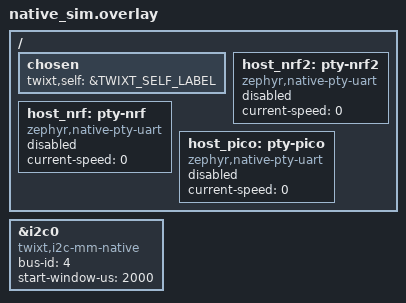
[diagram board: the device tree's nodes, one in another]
/*
 * Copyright (c) 2026 Christoph Jans <jans.christoph@gmail.com>
 *
 * SPDX-License-Identifier: Apache-2.0
 */

/* The bus on native_sim (twixt,i2c-mm-native); TWIXT_SELF_LABEL is mcu_<MCU>. The bridge's
 * ports to the host are PTYs (bridge.overlay enables them):
 * "pty-nrf2 connected to pseudotty: /dev/pts/N"
 */

/ {
	chosen {
		twixt,self = &TWIXT_SELF_LABEL;
	};

	host_nrf2: pty-nrf2 {
		compatible = "zephyr,native-pty-uart";
		current-speed = <0>;
		status = "disabled";
	};

	host_nrf: pty-nrf {
		compatible = "zephyr,native-pty-uart";
		current-speed = <0>;
		status = "disabled";
	};

	host_pico: pty-pico {
		compatible = "zephyr,native-pty-uart";
		current-speed = <0>;
		status = "disabled";
	};
};

&i2c0 {
	compatible = "twixt,i2c-mm-native";
	bus-id = <4>;

	/* The MCUs are processes that the host scheduler wakes up within about a
	 * millisecond of each other: that is what counts as "at the same moment"
	 */
	start-window-us = <2000>;

#include "../twixt_mcus.dtsi"
};
